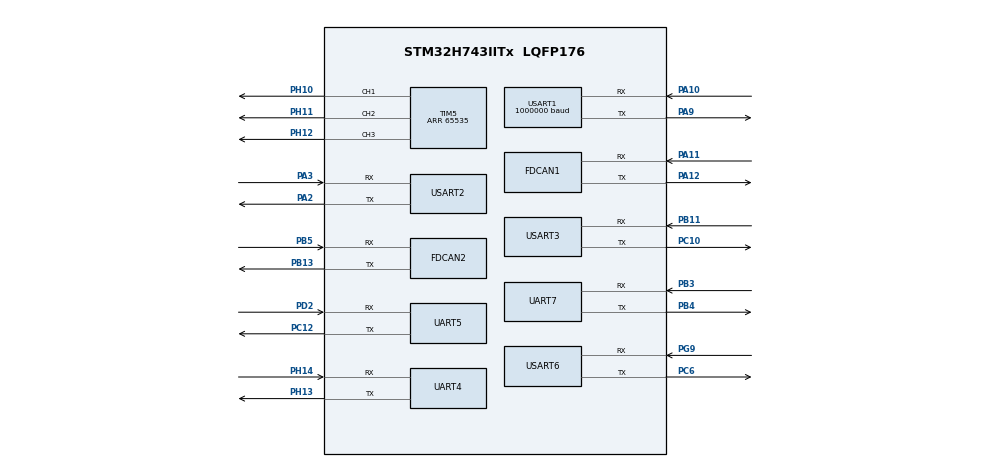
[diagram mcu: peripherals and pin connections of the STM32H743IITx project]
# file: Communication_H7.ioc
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CORTEX_M7.default_mode_Activation=0
Dma.Request0=USART1_RX
Dma.Request1=USART1_TX
Dma.Request10=USART6_RX
Dma.Request11=USART6_TX
Dma.Request12=UART4_RX
Dma.Request13=UART4_TX
Dma.Request2=USART2_RX
Dma.Request3=USART2_TX
Dma.Request4=UART7_RX
Dma.Request5=UART7_TX
Dma.Request6=UART5_RX
Dma.Request7=UART5_TX
Dma.Request8=USART3_RX
Dma.Request9=USART3_TX
Dma.UART4_RX.12.Direction=DMA_PERIPH_TO_MEMORY
Dma.UART4_RX.12.EventEnable=DISABLE
Dma.UART4_RX.12.FIFOMode=DMA_FIFOMODE_DISABLE
Dma.UART4_RX.12.Instance=DMA2_Stream4
Dma.UART4_RX.12.MemDataAlignment=DMA_MDATAALIGN_BYTE
Dma.UART4_RX.12.MemInc=DMA_MINC_ENABLE
Dma.UART4_RX.12.Mode=DMA_CIRCULAR
Dma.UART4_RX.12.PeriphDataAlignment=DMA_PDATAALIGN_BYTE
Dma.UART4_RX.12.PeriphInc=DMA_PINC_DISABLE
Dma.UART4_RX.12.Polarity=HAL_DMAMUX_REQ_GEN_RISING
Dma.UART4_RX.12.Priority=DMA_PRIORITY_LOW
Dma.UART4_RX.12.RequestNumber=1
Dma.UART4_RX.12.SignalID=NONE
Dma.UART4_RX.12.SyncEnable=DISABLE
Dma.UART4_RX.12.SyncPolarity=HAL_DMAMUX_SYNC_NO_EVENT
Dma.UART4_RX.12.SyncRequestNumber=1
Dma.UART4_RX.12.SyncSignalID=NONE
Dma.UART4_TX.13.Direction=DMA_MEMORY_TO_PERIPH
Dma.UART4_TX.13.EventEnable=DISABLE
Dma.UART4_TX.13.FIFOMode=DMA_FIFOMODE_DISABLE
Dma.UART4_TX.13.Instance=DMA2_Stream5
Dma.UART4_TX.13.MemDataAlignment=DMA_MDATAALIGN_BYTE
Dma.UART4_TX.13.MemInc=DMA_MINC_ENABLE
Dma.UART4_TX.13.Mode=DMA_NORMAL
Dma.UART4_TX.13.PeriphDataAlignment=DMA_PDATAALIGN_BYTE
Dma.UART4_TX.13.PeriphInc=DMA_PINC_DISABLE
Dma.UART4_TX.13.Polarity=HAL_DMAMUX_REQ_GEN_RISING
Dma.UART4_TX.13.Priority=DMA_PRIORITY_MEDIUM
Dma.UART4_TX.13.RequestNumber=1
Dma.UART4_TX.13.SignalID=NONE
Dma.UART4_TX.13.SyncEnable=DISABLE
Dma.UART4_TX.13.SyncPolarity=HAL_DMAMUX_SYNC_NO_EVENT
Dma.UART4_TX.13.SyncRequestNumber=1
Dma.UART4_TX.13.SyncSignalID=NONE
Dma.UART5_RX.6.Direction=DMA_PERIPH_TO_MEMORY
Dma.UART5_RX.6.EventEnable=DISABLE
Dma.UART5_RX.6.FIFOMode=DMA_FIFOMODE_DISABLE
Dma.UART5_RX.6.Instance=DMA1_Stream6
Dma.UART5_RX.6.MemDataAlignment=DMA_MDATAALIGN_BYTE
Dma.UART5_RX.6.MemInc=DMA_MINC_ENABLE
Dma.UART5_RX.6.Mode=DMA_CIRCULAR
Dma.UART5_RX.6.PeriphDataAlignment=DMA_PDATAALIGN_BYTE
Dma.UART5_RX.6.PeriphInc=DMA_PINC_DISABLE
Dma.UART5_RX.6.Polarity=HAL_DMAMUX_REQ_GEN_RISING
Dma.UART5_RX.6.Priority=DMA_PRIORITY_LOW
Dma.UART5_RX.6.RequestNumber=1
Dma.UART5_RX.6.SignalID=NONE
Dma.UART5_RX.6.SyncEnable=DISABLE
Dma.UART5_RX.6.SyncPolarity=HAL_DMAMUX_SYNC_NO_EVENT
Dma.UART5_RX.6.SyncRequestNumber=1
Dma.UART5_RX.6.SyncSignalID=NONE
Dma.UART5_TX.7.Direction=DMA_MEMORY_TO_PERIPH
Dma.UART5_TX.7.EventEnable=DISABLE
Dma.UART5_TX.7.FIFOMode=DMA_FIFOMODE_DISABLE
Dma.UART5_TX.7.Instance=DMA1_Stream7
Dma.UART5_TX.7.MemDataAlignment=DMA_MDATAALIGN_BYTE
Dma.UART5_TX.7.MemInc=DMA_MINC_ENABLE
Dma.UART5_TX.7.Mode=DMA_NORMAL
Dma.UART5_TX.7.PeriphDataAlignment=DMA_PDATAALIGN_BYTE
Dma.UART5_TX.7.PeriphInc=DMA_PINC_DISABLE
Dma.UART5_TX.7.Polarity=HAL_DMAMUX_REQ_GEN_RISING
Dma.UART5_TX.7.Priority=DMA_PRIORITY_LOW
Dma.UART5_TX.7.RequestNumber=1
Dma.UART5_TX.7.SignalID=NONE
Dma.UART5_TX.7.SyncEnable=DISABLE
Dma.UART5_TX.7.SyncPolarity=HAL_DMAMUX_SYNC_NO_EVENT
Dma.UART5_TX.7.SyncRequestNumber=1
Dma.UART5_TX.7.SyncSignalID=NONE
Dma.UART7_RX.4.Direction=DMA_PERIPH_TO_MEMORY
Dma.UART7_RX.4.EventEnable=DISABLE
Dma.UART7_RX.4.FIFOMode=DMA_FIFOMODE_DISABLE
Dma.UART7_RX.4.Instance=DMA1_Stream4
Dma.UART7_RX.4.MemDataAlignment=DMA_MDATAALIGN_BYTE
Dma.UART7_RX.4.MemInc=DMA_MINC_ENABLE
Dma.UART7_RX.4.Mode=DMA_CIRCULAR
Dma.UART7_RX.4.PeriphDataAlignment=DMA_PDATAALIGN_BYTE
Dma.UART7_RX.4.PeriphInc=DMA_PINC_DISABLE
Dma.UART7_RX.4.Polarity=HAL_DMAMUX_REQ_GEN_RISING
Dma.UART7_RX.4.Priority=DMA_PRIORITY_LOW
Dma.UART7_RX.4.RequestNumber=1
Dma.UART7_RX.4.SignalID=NONE
Dma.UART7_RX.4.SyncEnable=DISABLE
Dma.UART7_RX.4.SyncPolarity=HAL_DMAMUX_SYNC_NO_EVENT
Dma.UART7_RX.4.SyncRequestNumber=1
Dma.UART7_RX.4.SyncSignalID=NONE
Dma.UART7_TX.5.Direction=DMA_MEMORY_TO_PERIPH
Dma.UART7_TX.5.EventEnable=DISABLE
Dma.UART7_TX.5.FIFOMode=DMA_FIFOMODE_DISABLE
Dma.UART7_TX.5.Instance=DMA1_Stream5
Dma.UART7_TX.5.MemDataAlignment=DMA_MDATAALIGN_BYTE
Dma.UART7_TX.5.MemInc=DMA_MINC_ENABLE
Dma.UART7_TX.5.Mode=DMA_NORMAL
Dma.UART7_TX.5.PeriphDataAlignment=DMA_PDATAALIGN_BYTE
Dma.UART7_TX.5.PeriphInc=DMA_PINC_DISABLE
Dma.UART7_TX.5.Polarity=HAL_DMAMUX_REQ_GEN_RISING
Dma.UART7_TX.5.Priority=DMA_PRIORITY_LOW
Dma.UART7_TX.5.RequestNumber=1
Dma.UART7_TX.5.SignalID=NONE
Dma.UART7_TX.5.SyncEnable=DISABLE
Dma.UART7_TX.5.SyncPolarity=HAL_DMAMUX_SYNC_NO_EVENT
Dma.UART7_TX.5.SyncRequestNumber=1
Dma.UART7_TX.5.SyncSignalID=NONE
Dma.USART1_RX.0.Direction=DMA_PERIPH_TO_MEMORY
Dma.USART1_RX.0.EventEnable=DISABLE
Dma.USART1_RX.0.FIFOMode=DMA_FIFOMODE_DISABLE
Dma.USART1_RX.0.Instance=DMA1_Stream0
Dma.USART1_RX.0.MemDataAlignment=DMA_MDATAALIGN_BYTE
Dma.USART1_RX.0.MemInc=DMA_MINC_ENABLE
Dma.USART1_RX.0.Mode=DMA_CIRCULAR
Dma.USART1_RX.0.PeriphDataAlignment=DMA_PDATAALIGN_BYTE
Dma.USART1_RX.0.PeriphInc=DMA_PINC_DISABLE
Dma.USART1_RX.0.Polarity=HAL_DMAMUX_REQ_GEN_RISING
Dma.USART1_RX.0.Priority=DMA_PRIORITY_MEDIUM
Dma.USART1_RX.0.RequestNumber=1
Dma.USART1_RX.0.SignalID=NONE
Dma.USART1_RX.0.SyncEnable=DISABLE
Dma.USART1_RX.0.SyncPolarity=HAL_DMAMUX_SYNC_NO_EVENT
Dma.USART1_RX.0.SyncRequestNumber=1
Dma.USART1_RX.0.SyncSignalID=NONE
Dma.USART1_TX.1.Direction=DMA_MEMORY_TO_PERIPH
Dma.USART1_TX.1.EventEnable=DISABLE
Dma.USART1_TX.1.FIFOMode=DMA_FIFOMODE_DISABLE
Dma.USART1_TX.1.Instance=DMA1_Stream1
Dma.USART1_TX.1.MemDataAlignment=DMA_MDATAALIGN_BYTE
Dma.USART1_TX.1.MemInc=DMA_MINC_ENABLE
Dma.USART1_TX.1.Mode=DMA_NORMAL
Dma.USART1_TX.1.PeriphDataAlignment=DMA_PDATAALIGN_BYTE
Dma.USART1_TX.1.PeriphInc=DMA_PINC_DISABLE
Dma.USART1_TX.1.Polarity=HAL_DMAMUX_REQ_GEN_RISING
Dma.USART1_TX.1.Priority=DMA_PRIORITY_MEDIUM
Dma.USART1_TX.1.RequestNumber=1
Dma.USART1_TX.1.SignalID=NONE
Dma.USART1_TX.1.SyncEnable=DISABLE
Dma.USART1_TX.1.SyncPolarity=HAL_DMAMUX_SYNC_NO_EVENT
Dma.USART1_TX.1.SyncRequestNumber=1
Dma.USART1_TX.1.SyncSignalID=NONE
Dma.USART2_RX.2.Direction=DMA_PERIPH_TO_MEMORY
Dma.USART2_RX.2.EventEnable=DISABLE
Dma.USART2_RX.2.FIFOMode=DMA_FIFOMODE_DISABLE
Dma.USART2_RX.2.Instance=DMA1_Stream2
Dma.USART2_RX.2.MemDataAlignment=DMA_MDATAALIGN_BYTE
Dma.USART2_RX.2.MemInc=DMA_MINC_ENABLE
Dma.USART2_RX.2.Mode=DMA_CIRCULAR
Dma.USART2_RX.2.PeriphDataAlignment=DMA_PDATAALIGN_BYTE
Dma.USART2_RX.2.PeriphInc=DMA_PINC_DISABLE
Dma.USART2_RX.2.Polarity=HAL_DMAMUX_REQ_GEN_RISING
Dma.USART2_RX.2.Priority=DMA_PRIORITY_LOW
Dma.USART2_RX.2.RequestNumber=1
Dma.USART2_RX.2.SignalID=NONE
Dma.USART2_RX.2.SyncEnable=DISABLE
Dma.USART2_RX.2.SyncPolarity=HAL_DMAMUX_SYNC_NO_EVENT
Dma.USART2_RX.2.SyncRequestNumber=1
Dma.USART2_RX.2.SyncSignalID=NONE
Dma.USART2_TX.3.Direction=DMA_MEMORY_TO_PERIPH
Dma.USART2_TX.3.EventEnable=DISABLE
Dma.USART2_TX.3.FIFOMode=DMA_FIFOMODE_DISABLE
Dma.USART2_TX.3.Instance=DMA1_Stream3
Dma.USART2_TX.3.MemDataAlignment=DMA_MDATAALIGN_BYTE
Dma.USART2_TX.3.MemInc=DMA_MINC_ENABLE
Dma.USART2_TX.3.Mode=DMA_NORMAL
Dma.USART2_TX.3.PeriphDataAlignment=DMA_PDATAALIGN_BYTE
Dma.USART2_TX.3.PeriphInc=DMA_PINC_DISABLE
Dma.USART2_TX.3.Polarity=HAL_DMAMUX_REQ_GEN_RISING
Dma.USART2_TX.3.Priority=DMA_PRIORITY_LOW
Dma.USART2_TX.3.RequestNumber=1
Dma.USART2_TX.3.SignalID=NONE
Dma.USART2_TX.3.SyncEnable=DISABLE
Dma.USART2_TX.3.SyncPolarity=HAL_DMAMUX_SYNC_NO_EVENT
Dma.USART2_TX.3.SyncRequestNumber=1
Dma.USART2_TX.3.SyncSignalID=NONE
Dma.USART3_RX.8.Direction=DMA_PERIPH_TO_MEMORY
Dma.USART3_RX.8.EventEnable=DISABLE
Dma.USART3_RX.8.FIFOMode=DMA_FIFOMODE_DISABLE
Dma.USART3_RX.8.Instance=DMA2_Stream0
Dma.USART3_RX.8.MemDataAlignment=DMA_MDATAALIGN_BYTE
Dma.USART3_RX.8.MemInc=DMA_MINC_ENABLE
Dma.USART3_RX.8.Mode=DMA_CIRCULAR
Dma.USART3_RX.8.PeriphDataAlignment=DMA_PDATAALIGN_BYTE
Dma.USART3_RX.8.PeriphInc=DMA_PINC_DISABLE
Dma.USART3_RX.8.Polarity=HAL_DMAMUX_REQ_GEN_RISING
Dma.USART3_RX.8.Priority=DMA_PRIORITY_LOW
Dma.USART3_RX.8.RequestNumber=1
Dma.USART3_RX.8.SignalID=NONE
Dma.USART3_RX.8.SyncEnable=DISABLE
Dma.USART3_RX.8.SyncPolarity=HAL_DMAMUX_SYNC_NO_EVENT
Dma.USART3_RX.8.SyncRequestNumber=1
Dma.USART3_RX.8.SyncSignalID=NONE
Dma.USART3_TX.9.Direction=DMA_MEMORY_TO_PERIPH
Dma.USART3_TX.9.EventEnable=DISABLE
Dma.USART3_TX.9.FIFOMode=DMA_FIFOMODE_DISABLE
Dma.USART3_TX.9.Instance=DMA2_Stream1
Dma.USART3_TX.9.MemDataAlignment=DMA_MDATAALIGN_BYTE
Dma.USART3_TX.9.MemInc=DMA_MINC_ENABLE
Dma.USART3_TX.9.Mode=DMA_NORMAL
Dma.USART3_TX.9.PeriphDataAlignment=DMA_PDATAALIGN_BYTE
Dma.USART3_TX.9.PeriphInc=DMA_PINC_DISABLE
Dma.USART3_TX.9.Polarity=HAL_DMAMUX_REQ_GEN_RISING
Dma.USART3_TX.9.Priority=DMA_PRIORITY_LOW
Dma.USART3_TX.9.RequestNumber=1
Dma.USART3_TX.9.SignalID=NONE
Dma.USART3_TX.9.SyncEnable=DISABLE
Dma.USART3_TX.9.SyncPolarity=HAL_DMAMUX_SYNC_NO_EVENT
Dma.USART3_TX.9.SyncRequestNumber=1
Dma.USART3_TX.9.SyncSignalID=NONE
Dma.USART6_RX.10.Direction=DMA_PERIPH_TO_MEMORY
Dma.USART6_RX.10.EventEnable=DISABLE
Dma.USART6_RX.10.FIFOMode=DMA_FIFOMODE_DISABLE
Dma.USART6_RX.10.Instance=DMA2_Stream2
Dma.USART6_RX.10.MemDataAlignment=DMA_MDATAALIGN_BYTE
Dma.USART6_RX.10.MemInc=DMA_MINC_ENABLE
Dma.USART6_RX.10.Mode=DMA_CIRCULAR
Dma.USART6_RX.10.PeriphDataAlignment=DMA_PDATAALIGN_BYTE
Dma.USART6_RX.10.PeriphInc=DMA_PINC_DISABLE
Dma.USART6_RX.10.Polarity=HAL_DMAMUX_REQ_GEN_RISING
Dma.USART6_RX.10.Priority=DMA_PRIORITY_LOW
Dma.USART6_RX.10.RequestNumber=1
Dma.USART6_RX.10.SignalID=NONE
Dma.USART6_RX.10.SyncEnable=DISABLE
Dma.USART6_RX.10.SyncPolarity=HAL_DMAMUX_SYNC_NO_EVENT
Dma.USART6_RX.10.SyncRequestNumber=1
Dma.USART6_RX.10.SyncSignalID=NONE
Dma.USART6_TX.11.Direction=DMA_MEMORY_TO_PERIPH
Dma.USART6_TX.11.EventEnable=DISABLE
Dma.USART6_TX.11.FIFOMode=DMA_FIFOMODE_DISABLE
Dma.USART6_TX.11.Instance=DMA2_Stream3
Dma.USART6_TX.11.MemDataAlignment=DMA_MDATAALIGN_BYTE
Dma.USART6_TX.11.MemInc=DMA_MINC_ENABLE
Dma.USART6_TX.11.Mode=DMA_NORMAL
Dma.USART6_TX.11.PeriphDataAlignment=DMA_PDATAALIGN_BYTE
Dma.USART6_TX.11.PeriphInc=DMA_PINC_DISABLE
Dma.USART6_TX.11.Polarity=HAL_DMAMUX_REQ_GEN_RISING
Dma.USART6_TX.11.Priority=DMA_PRIORITY_LOW
Dma.USART6_TX.11.RequestNumber=1
Dma.USART6_TX.11.SignalID=NONE
Dma.USART6_TX.11.SyncEnable=DISABLE
Dma.USART6_TX.11.SyncPolarity=HAL_DMAMUX_SYNC_NO_EVENT
Dma.USART6_TX.11.SyncRequestNumber=1
Dma.USART6_TX.11.SyncSignalID=NONE
FDCAN1.CalculateBaudRateNominal=1000000
FDCAN1.CalculateTimeBitNominal=1000
FDCAN1.CalculateTimeQuantumNominal=25.0
FDCAN1.ClockCalibrationCCU=DISABLE
FDCAN1.DataPrescaler=3
FDCAN1.DataSyncJumpWidth=10
FDCAN1.DataTimeSeg1=29
FDCAN1.DataTimeSeg2=10
FDCAN1.NominalPrescaler=3
FDCAN1.NominalSyncJumpWidth=10
FDCAN1.NominalTimeSeg1=29
FDCAN1.NominalTimeSeg2=10
FDCAN1.RxFifo0ElmtsNbr=4
FDCAN1.StdFiltersNbr=1
FDCAN1.TxBuffersNbr=0
FDCAN1.TxFifoQueueElmtsNbr=32
FDCAN1.TxFifoQueueMode=FDCAN_TX_FIFO_OPERATION
FDCAN2.CalculateBaudRateNominal=1000000
FDCAN2.CalculateTimeBitNominal=1000
FDCAN2.CalculateTimeQuantumNominal=25.0
FDCAN2.DataPrescaler=3
FDCAN2.DataSyncJumpWidth=10
FDCAN2.DataTimeSeg1=29
FDCAN2.DataTimeSeg2=10
FDCAN2.NominalPrescaler=3
FDCAN2.NominalSyncJumpWidth=10
FDCAN2.NominalTimeSeg1=29
FDCAN2.NominalTimeSeg2=10
FDCAN2.RxFifo0ElmtsNbr=4
FDCAN2.StdFiltersNbr=1
FDCAN2.TxBuffersNbr=0
FDCAN2.TxFifoQueueElmtsNbr=32
FREERTOS.Tasks01=defaultTask,0,128,StartDefaultTask,Default,NULL,Dynamic,NULL,NULL
FREERTOS.configGENERATE_RUN_TIME_STATS=1
FREERTOS.configLIBRARY_MAX_SYSCALL_INTERRUPT_PRIORITY=5
FREERTOS.configUSE_COUNTING_SEMAPHORES=0
FREERTOS.configUSE_STATS_FORMATTING_FUNCTIONS=1
FREERTOS.configUSE_TRACE_FACILITY=1
Mcu.Family=STM32H7
Mcu.Name=STM32H743IITx
Mcu.Package=LQFP176
NVIC.DMA1_Stream0_IRQn=true\:5\:0\:false\:false\:true\:true\:false\:true\:true
NVIC.DMA1_Stream1_IRQn=true\:5\:0\:false\:false\:true\:true\:false\:true\:true
NVIC.DMA1_Stream2_IRQn=true\:5\:0\:false\:false\:true\:true\:false\:true\:true
NVIC.DMA1_Stream3_IRQn=true\:5\:0\:false\:false\:true\:true\:false\:true\:true
NVIC.DMA1_Stream4_IRQn=true\:5\:0\:false\:false\:true\:true\:false\:true\:true
NVIC.DMA1_Stream5_IRQn=true\:5\:0\:false\:false\:true\:true\:false\:true\:true
NVIC.DMA1_Stream6_IRQn=true\:5\:0\:false\:false\:true\:true\:false\:true\:true
NVIC.DMA1_Stream7_IRQn=true\:5\:0\:false\:false\:true\:true\:false\:true\:true
NVIC.DMA2_Stream0_IRQn=true\:5\:0\:false\:false\:true\:true\:false\:true\:true
NVIC.DMA2_Stream1_IRQn=true\:5\:0\:false\:false\:true\:true\:false\:true\:true
NVIC.DMA2_Stream2_IRQn=true\:5\:0\:false\:false\:true\:true\:false\:true\:true
NVIC.DMA2_Stream3_IRQn=true\:5\:0\:false\:false\:true\:true\:false\:true\:true
NVIC.DMA2_Stream4_IRQn=true\:5\:0\:false\:false\:true\:true\:false\:true\:true
NVIC.DMA2_Stream5_IRQn=true\:5\:0\:false\:false\:true\:true\:false\:true\:true
NVIC.FDCAN1_IT0_IRQn=true\:5\:0\:false\:false\:true\:true\:true\:true\:true
NVIC.FDCAN2_IT0_IRQn=true\:5\:0\:false\:false\:true\:true\:true\:true\:true
NVIC.PriorityGroup=NVIC_PRIORITYGROUP_4
NVIC.TIM6_DAC_IRQn=true\:5\:0\:false\:false\:true\:true\:true\:true\:true
NVIC.TIM7_IRQn=true\:5\:0\:false\:false\:true\:true\:true\:true\:true
NVIC.UART4_IRQn=true\:5\:0\:false\:false\:true\:true\:true\:true\:true
NVIC.UART5_IRQn=true\:5\:0\:false\:false\:true\:true\:true\:true\:true
NVIC.UART7_IRQn=true\:5\:0\:false\:false\:true\:true\:true\:true\:true
NVIC.USART1_IRQn=true\:5\:0\:false\:false\:true\:true\:false\:true\:true
NVIC.USART2_IRQn=true\:5\:0\:false\:false\:true\:true\:true\:true\:true
NVIC.USART3_IRQn=true\:5\:0\:false\:false\:true\:true\:true\:true\:true
NVIC.USART6_IRQn=true\:5\:0\:false\:false\:true\:true\:true\:true\:true
PA10.Mode=Asynchronous
PA10.Signal=USART1_RX
PA11.Mode=FDCAN_Activate
PA11.Signal=FDCAN1_RX
PA12.Mode=FDCAN_Activate
PA12.Signal=FDCAN1_TX
PA13\ (JTMS/SWDIO).Mode=Serial_Wire
PA13\ (JTMS/SWDIO).Signal=DEBUG_JTMS-SWDIO
PA14\ (JTCK/SWCLK).Mode=Serial_Wire
PA14\ (JTCK/SWCLK).Signal=DEBUG_JTCK-SWCLK
PA2.Mode=Asynchronous
PA2.Signal=USART2_TX
PA3.Mode=Asynchronous
PA3.Signal=USART2_RX
PA9.Mode=Asynchronous
PA9.Signal=USART1_TX
PB11.Mode=Asynchronous
PB11.Signal=USART3_RX
PB13.Mode=FDCAN_Activate
PB13.Signal=FDCAN2_TX
PB3\ (JTDO/TRACESWO).Mode=Asynchronous
PB3\ (JTDO/TRACESWO).Signal=UART7_RX
PB4\ (NJTRST).Mode=Asynchronous
PB4\ (NJTRST).Signal=UART7_TX
PB5.Mode=FDCAN_Activate
PB5.Signal=FDCAN2_RX
PC10.Mode=Asynchronous
PC10.Signal=USART3_TX
PC12.Mode=Asynchronous
PC12.Signal=UART5_TX
PC6.Mode=Asynchronous
PC6.Signal=USART6_TX
PD2.Mode=Asynchronous
PD2.Signal=UART5_RX
PG9.Mode=Asynchronous
PG9.Signal=USART6_RX
PH0-OSC_IN\ (PH0).Mode=HSE-External-Oscillator
PH0-OSC_IN\ (PH0).Signal=RCC_OSC_IN
PH1-OSC_OUT\ (PH1).Mode=HSE-External-Oscillator
PH1-OSC_OUT\ (PH1).Signal=RCC_OSC_OUT
PH10.Signal=S_TIM5_CH1
PH11.Signal=S_TIM5_CH2
PH12.Signal=S_TIM5_CH3
PH13.Mode=Asynchronous
PH13.Signal=UART4_TX
PH14.Mode=Asynchronous
PH14.Signal=UART4_RX
ProjectManager.HeapSize=0x200
ProjectManager.StackSize=0xFFF
ProjectManager.TargetToolchain=MDK-ARM V5.32
RCC.ADCFreq_Value=120000000
RCC.APB1Freq_Value=120000000
RCC.APB2Freq_Value=120000000
RCC.APB3Freq_Value=120000000
RCC.APB4Freq_Value=120000000
RCC.CortexFreq_Value=480000000
RCC.D1PPRE=RCC_APB3_DIV2
RCC.D2PPRE1=RCC_APB1_DIV2
RCC.D2PPRE2=RCC_APB2_DIV2
RCC.D3PPRE=RCC_APB4_DIV2
RCC.DIVM1=5
RCC.DIVM2=25
RCC.DIVN1=192
RCC.DIVN2=240
RCC.DIVQ1=8
RCC.FDCANCLockSelection=RCC_FDCANCLKSOURCE_PLL2
RCC.HCLKFreq_Value=240000000
RCC.HPRE=RCC_HCLK_DIV2
RCC.PLL2FRACN=0
RCC.PLL2_VCI_Range-AdvancedSettings=RCC_PLL2VCIRANGE_0
RCC.PLL3FRACN=0
RCC.PLLFRACN=0
RCC.PLLSourceVirtual=RCC_PLLSOURCE_HSE
RCC.SYSCLKFreq_VALUE=480000000
RCC.SYSCLKSource=RCC_SYSCLKSOURCE_PLLCLK
RCC.USBFreq_Value=120000000
SH.S_TIM5_CH1.0=TIM5_CH1,PWM Generation1 CH1
SH.S_TIM5_CH2.0=TIM5_CH2,PWM Generation2 CH2
SH.S_TIM5_CH3.0=TIM5_CH3,PWM Generation3 CH3
TIM5.Channel-PWM\ Generation1\ CH1=TIM_CHANNEL_1
TIM5.Channel-PWM\ Generation2\ CH2=TIM_CHANNEL_2
TIM5.Channel-PWM\ Generation3\ CH3=TIM_CHANNEL_3
TIM5.Period=65535
TIM6.Period=50-1
TIM6.Prescaler=240-1
TIM7.Period=9999
TIM7.Prescaler=240-1
USART1.BaudRate=1000000
USART1.VirtualMode-Asynchronous=VM_ASYNC
USART2.VirtualMode-Asynchronous=VM_ASYNC
USART3.VirtualMode-Asynchronous=VM_ASYNC
USART6.VirtualMode-Asynchronous=VM_ASYNC
VP_FREERTOS_VS_CMSIS_V1.Mode=CMSIS_V1
VP_MEMORYMAP_VS_MEMORYMAP.Mode=CurAppReg
VP_TIM5_VS_ClockSourceINT.Mode=Internal
VP_TIM6_VS_ClockSourceINT.Mode=Enable_Timer
VP_TIM7_VS_ClockSourceINT.Mode=Enable_Timer
board=custom

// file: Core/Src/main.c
/* USER CODE BEGIN Header */
/**
  ******************************************************************************
  * @file           : main.c
  * @brief          : Main program body
  ******************************************************************************
  * @attention
  *
  * Copyright (c) 2026 STMicroelectronics.
  * All rights reserved.
  *
  * This software is licensed under terms that can be found in the LICENSE file
  * in the root directory of this software component.
  * If no LICENSE file comes with this software, it is provided AS-IS.
  *
  ******************************************************************************
  */
/* USER CODE END Header */
#include "main.h"
#include "cmsis_os.h"
#include "dma.h"
#include "fdcan.h"
#include "tim.h"
#include "usart.h"
#include "gpio.h"

/* USER CODE BEGIN Includes */
#include "INIT.h"
#include "bsp_timer.h"
/* USER CODE END Includes */

void SystemClock_Config(void);
void PeriphCommonClock_Config(void);
void MX_FREERTOS_Init(void);

int main(void)
{

  /* MCU Configuration--------------------------------------------------------*/

  /* Reset of all peripherals, Initializes the Flash interface and the Systick. */
  HAL_Init();

  /* Configure the system clock */
  SystemClock_Config();

  /* Configure the peripherals common clocks */
  PeriphCommonClock_Config();

  /* Initialize all configured peripherals */
  MX_GPIO_Init();
  MX_DMA_Init();
  MX_USART1_UART_Init();
  MX_TIM5_Init();
  MX_USART2_UART_Init();
  MX_UART4_Init();
  MX_UART5_Init();
  MX_UART7_Init();
  MX_USART3_UART_Init();
  MX_USART6_UART_Init();
  MX_FDCAN1_Init();
  MX_FDCAN2_Init();
  MX_TIM7_Init();
  MX_TIM6_Init();
  /* USER CODE BEGIN 2 */
  INIT();
  /* USER CODE END 2 */

  /* Call init function for freertos objects (in cmsis_os2.c) */
  MX_FREERTOS_Init();

  /* Start scheduler */
  osKernelStart();

  /* We should never get here as control is now taken by the scheduler */

  /* Infinite loop */
  while (1)
  {

  }
}

void SystemClock_Config(void)
{
  RCC_OscInitTypeDef RCC_OscInitStruct = {0};
  RCC_ClkInitTypeDef RCC_ClkInitStruct = {0};

  /** Supply configuration update enable
  */
  HAL_PWREx_ConfigSupply(PWR_LDO_SUPPLY);

  /** Configure the main internal regulator output voltage
  */
  __HAL_PWR_VOLTAGESCALING_CONFIG(PWR_REGULATOR_VOLTAGE_SCALE0);

  while(!__HAL_PWR_GET_FLAG(PWR_FLAG_VOSRDY)) {}

  /** Initializes the RCC Oscillators according to the specified parameters
  * in the RCC_OscInitTypeDef structure.
  */
  RCC_OscInitStruct.OscillatorType = RCC_OSCILLATORTYPE_HSE;
  RCC_OscInitStruct.HSEState = RCC_HSE_ON;
  RCC_OscInitStruct.PLL.PLLState = RCC_PLL_ON;
  RCC_OscInitStruct.PLL.PLLSource = RCC_PLLSOURCE_HSE;
  RCC_OscInitStruct.PLL.PLLM = 5;
  RCC_OscInitStruct.PLL.PLLN = 192;
  RCC_OscInitStruct.PLL.PLLP = 2;
  RCC_OscInitStruct.PLL.PLLQ = 8;
  RCC_OscInitStruct.PLL.PLLR = 2;
  RCC_OscInitStruct.PLL.PLLRGE = RCC_PLL1VCIRANGE_2;
  RCC_OscInitStruct.PLL.PLLVCOSEL = RCC_PLL1VCOWIDE;
  RCC_OscInitStruct.PLL.PLLFRACN = 0;
  if (HAL_RCC_OscConfig(&RCC_OscInitStruct) != HAL_OK)
  {
    Error_Handler();
  }

  /** Initializes the CPU, AHB and APB buses clocks
  */
  RCC_ClkInitStruct.ClockType = RCC_CLOCKTYPE_HCLK|RCC_CLOCKTYPE_SYSCLK
                              |RCC_CLOCKTYPE_PCLK1|RCC_CLOCKTYPE_PCLK2
                              |RCC_CLOCKTYPE_D3PCLK1|RCC_CLOCKTYPE_D1PCLK1;
  RCC_ClkInitStruct.SYSCLKSource = RCC_SYSCLKSOURCE_PLLCLK;
  RCC_ClkInitStruct.SYSCLKDivider = RCC_SYSCLK_DIV1;
  RCC_ClkInitStruct.AHBCLKDivider = RCC_HCLK_DIV2;
  RCC_ClkInitStruct.APB3CLKDivider = RCC_APB3_DIV2;
  RCC_ClkInitStruct.APB1CLKDivider = RCC_APB1_DIV2;
  RCC_ClkInitStruct.APB2CLKDivider = RCC_APB2_DIV2;
  RCC_ClkInitStruct.APB4CLKDivider = RCC_APB4_DIV2;

  if (HAL_RCC_ClockConfig(&RCC_ClkInitStruct, FLASH_LATENCY_4) != HAL_OK)
  {
    Error_Handler();
  }
}

void PeriphCommonClock_Config(void)
{
  RCC_PeriphCLKInitTypeDef PeriphClkInitStruct = {0};

  /** Initializes the peripherals clock
  */
  PeriphClkInitStruct.PeriphClockSelection = RCC_PERIPHCLK_FDCAN;
  PeriphClkInitStruct.PLL2.PLL2M = 25;
  PeriphClkInitStruct.PLL2.PLL2N = 240;
  PeriphClkInitStruct.PLL2.PLL2P = 2;
  PeriphClkInitStruct.PLL2.PLL2Q = 2;
  PeriphClkInitStruct.PLL2.PLL2R = 2;
  PeriphClkInitStruct.PLL2.PLL2RGE = RCC_PLL2VCIRANGE_0;
  PeriphClkInitStruct.PLL2.PLL2VCOSEL = RCC_PLL2VCOWIDE;
  PeriphClkInitStruct.PLL2.PLL2FRACN = 0;
  PeriphClkInitStruct.FdcanClockSelection = RCC_FDCANCLKSOURCE_PLL2;
  if (HAL_RCCEx_PeriphCLKConfig(&PeriphClkInitStruct) != HAL_OK)
  {
    Error_Handler();
  }
}

void Error_Handler(void)
{
  __disable_irq();
  while (1)
  {
  }
}

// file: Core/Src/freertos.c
/* USER CODE BEGIN Header */
/**
  ******************************************************************************
  * File Name          : freertos.c
  * Description        : Code for freertos applications
  ******************************************************************************
  * @attention
  *
  * Copyright (c) 2026 STMicroelectronics.
  * All rights reserved.
  *
  * This software is licensed under terms that can be found in the LICENSE file
  * in the root directory of this software component.
  * If no LICENSE file comes with this software, it is provided AS-IS.
  *
  ******************************************************************************
  */
/* USER CODE END Header */

#include "FreeRTOS.h"
#include "task.h"
#include "main.h"
#include "cmsis_os.h"

/* USER CODE BEGIN Variables */
#include "bsp_timer.h"
/* USER CODE END Variables */
osThreadId defaultTaskHandle;

void StartDefaultTask(void const * argument);

void MX_FREERTOS_Init(void); /* (MISRA C 2004 rule 8.1) */

/* GetIdleTaskMemory prototype (linked to static allocation support) */
void vApplicationGetIdleTaskMemory( StaticTask_t **ppxIdleTaskTCBBuffer, StackType_t **ppxIdleTaskStackBuffer, uint32_t *pulIdleTaskStackSize );

/* Hook prototypes */
void configureTimerForRunTimeStats(void);
unsigned long getRunTimeCounterValue(void);

/* USER CODE BEGIN 1 */
/* Functions needed when configGENERATE_RUN_TIME_STATS is on */
__weak void configureTimerForRunTimeStats(void)
{
  htim6_DEBUG_counter=0;
}

__weak unsigned long getRunTimeCounterValue(void)
{
return htim6_DEBUG_counter;
}
/* USER CODE END 1 */

/* USER CODE BEGIN GET_IDLE_TASK_MEMORY */
static StaticTask_t xIdleTaskTCBBuffer;
static StackType_t xIdleStack[configMINIMAL_STACK_SIZE];

void vApplicationGetIdleTaskMemory( StaticTask_t **ppxIdleTaskTCBBuffer, StackType_t **ppxIdleTaskStackBuffer, uint32_t *pulIdleTaskStackSize )
{
  *ppxIdleTaskTCBBuffer = &xIdleTaskTCBBuffer;
  *ppxIdleTaskStackBuffer = &xIdleStack[0];
  *pulIdleTaskStackSize = configMINIMAL_STACK_SIZE;
  /* place for user code */
}
/* USER CODE END GET_IDLE_TASK_MEMORY */

void MX_FREERTOS_Init(void) {

  /* Create the thread(s) */
  /* definition and creation of defaultTask */
  osThreadDef(defaultTask, StartDefaultTask, osPriorityNormal, 0, 128);
  defaultTaskHandle = osThreadCreate(osThread(defaultTask), NULL);

}

void StartDefaultTask(void const * argument)
{
  for(;;)
  {
    osDelay(1);
  }
}
